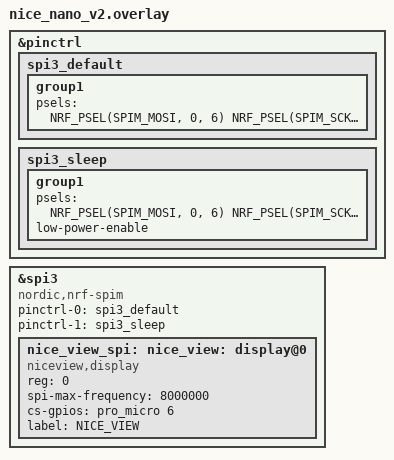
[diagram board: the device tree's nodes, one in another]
/*
 * nice_nano_v2-specific bindings for the nice!view shield.
 * This enables the SPI controller and creates the display device
 * as a child of that SPI controller. The node is labelled with
 * both `nice_view_spi` (for SPI-specific overrides) and `nice_view`
 * (pointed to by zmk,display).
 */

&pinctrl {
    spi3_default: spi3_default {
        group1 {
            /* MOSI and SCK pins used by the nice_nano_v2 layout.
               Adjust indices if you wired differently. */
            psels = <NRF_PSEL(SPIM_MOSI, 0, 6) NRF_PSEL(SPIM_SCK, 0, 8)>;
        };
    };

    spi3_sleep: spi3_sleep {
        group1 {
            psels = <NRF_PSEL(SPIM_MOSI, 0, 6) NRF_PSEL(SPIM_SCK, 0, 8)>;
            low-power-enable;
        };
    };
};

&spi3 {
    compatible = "nordic,nrf-spim";
    status = "okay";

    pinctrl-0 = <&spi3_default>;
    pinctrl-1 = <&spi3_sleep>;
    pinctrl-names = "default", "sleep";

    /*
     * The display device itself is a child of the SPI controller.
     * Assign two labels so both `&nice_view` and `&nice_view_spi` resolve:
     *   - &nice_view  -> used by chosen { zmk,display = &nice_view; }
     *   - &nice_view_spi -> used by shield/board overrides (CS pin overrides)
     */
    nice_view_spi: nice_view: display@0 {
        compatible = "niceview,display";
        reg = <0>;
        spi-max-frequency = <8000000>;

        /* CS pin: D1 on nice!nano v2 -> &pro_micro 6
           If you wired CS to another pin change the index. */
        cs-gpios = <&pro_micro 6 GPIO_ACTIVE_HIGH>;

        label = "NICE_VIEW";
    };
};
